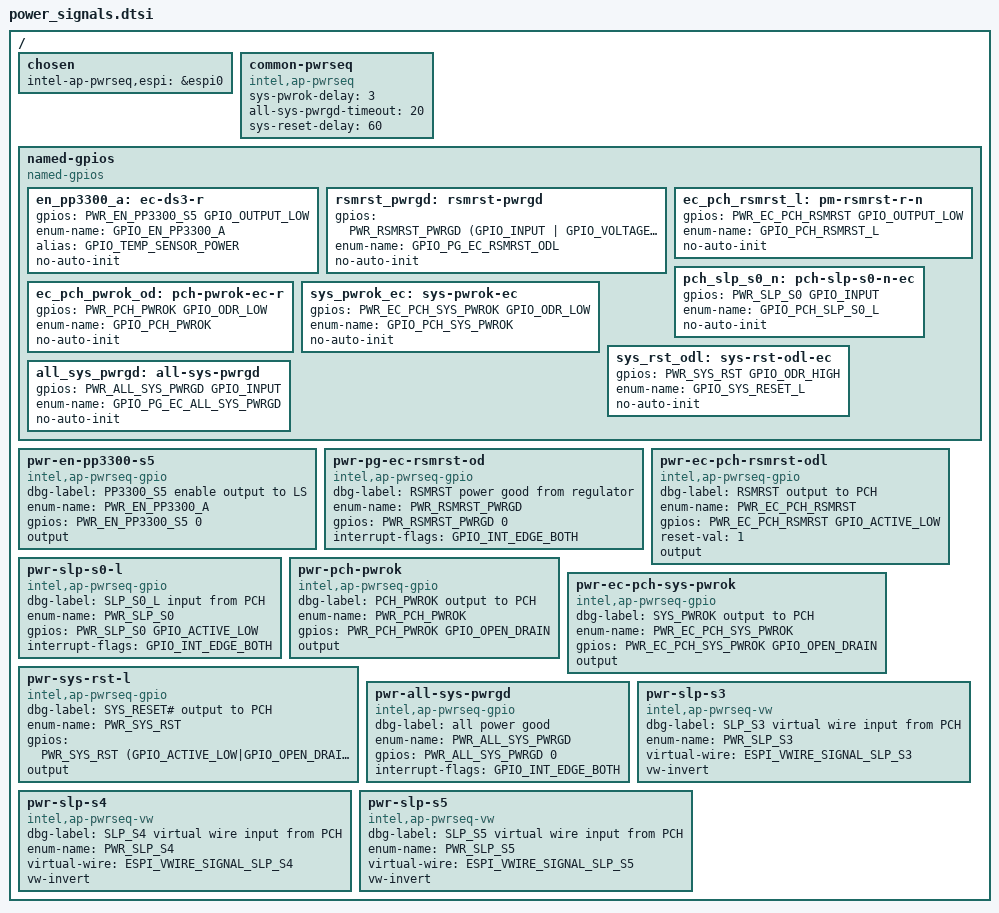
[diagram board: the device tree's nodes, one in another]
/* Copyright 2024 The ChromiumOS Authors
 * Use of this source code is governed by a BSD-style license that can be
 * found in the LICENSE file.
 */

/ {
        chosen {
		intel-ap-pwrseq,espi = &espi0;
	};

	common-pwrseq {
		compatible = "intel,ap-pwrseq";

		sys-pwrok-delay = <3>;
		all-sys-pwrgd-timeout = <20>;
		sys-reset-delay = <60>;
	};

	named-gpios {
		compatible = "named-gpios";

		en_pp3300_a: ec-ds3-r {
			gpios = <PWR_EN_PP3300_S5 GPIO_OUTPUT_LOW>;
			enum-name = "GPIO_EN_PP3300_A";
			alias = "GPIO_TEMP_SENSOR_POWER";
		};

		rsmrst_pwrgd: rsmrst-pwrgd {
			gpios = <PWR_RSMRST_PWRGD (GPIO_INPUT | GPIO_VOLTAGE_1P8)>;
			enum-name = "GPIO_PG_EC_RSMRST_ODL";
		};

		ec_pch_rsmrst_l: pm-rsmrst-r-n {
			gpios = <PWR_EC_PCH_RSMRST GPIO_OUTPUT_LOW>; /* 1.8V */
			enum-name = "GPIO_PCH_RSMRST_L";
		};

		pch_slp_s0_n: pch-slp-s0-n-ec {
			gpios = <PWR_SLP_S0 GPIO_INPUT>;
			enum-name = "GPIO_PCH_SLP_S0_L"; /* 1.8V */
		};

		ec_pch_pwrok_od: pch-pwrok-ec-r {
			gpios = <PWR_PCH_PWROK GPIO_ODR_LOW>;
			enum-name = "GPIO_PCH_PWROK";
		};

		sys_pwrok_ec: sys-pwrok-ec {
			gpios = <PWR_EC_PCH_SYS_PWROK GPIO_ODR_LOW>;
			enum-name = "GPIO_PCH_SYS_PWROK";
		};

		sys_rst_odl: sys-rst-odl-ec {
			gpios = <PWR_SYS_RST GPIO_ODR_HIGH>;
			enum-name = "GPIO_SYS_RESET_L";
		};

		all_sys_pwrgd: all-sys-pwrgd {
			gpios = <PWR_ALL_SYS_PWRGD GPIO_INPUT>;
			enum-name = "GPIO_PG_EC_ALL_SYS_PWRGD";
		};
	};

	pwr-en-pp3300-s5 {
		compatible = "intel,ap-pwrseq-gpio";
		dbg-label = "PP3300_S5 enable output to LS";
		enum-name = "PWR_EN_PP3300_A";
		gpios = <PWR_EN_PP3300_S5 0>;
		output;
	};

	pwr-pg-ec-rsmrst-od {
		compatible = "intel,ap-pwrseq-gpio";
		dbg-label = "RSMRST power good from regulator";
		enum-name = "PWR_RSMRST_PWRGD";
		gpios = <PWR_RSMRST_PWRGD 0>;
		interrupt-flags = <GPIO_INT_EDGE_BOTH>;
	};

	pwr-ec-pch-rsmrst-odl {
		compatible = "intel,ap-pwrseq-gpio";
		dbg-label = "RSMRST output to PCH";
		enum-name = "PWR_EC_PCH_RSMRST";
		gpios = <PWR_EC_PCH_RSMRST GPIO_ACTIVE_LOW>;
		reset-val = <1>;
		output;
	};

	pwr-slp-s0-l {
		compatible = "intel,ap-pwrseq-gpio";
		dbg-label = "SLP_S0_L input from PCH";
		enum-name = "PWR_SLP_S0";
		gpios = <PWR_SLP_S0 GPIO_ACTIVE_LOW>;
		interrupt-flags = <GPIO_INT_EDGE_BOTH>;
	};

	pwr-pch-pwrok {
		compatible = "intel,ap-pwrseq-gpio";
		dbg-label = "PCH_PWROK output to PCH";
		enum-name = "PWR_PCH_PWROK";
		gpios = <PWR_PCH_PWROK GPIO_OPEN_DRAIN>;
		output;
	};

	pwr-ec-pch-sys-pwrok {
		compatible = "intel,ap-pwrseq-gpio";
		dbg-label = "SYS_PWROK output to PCH";
		enum-name = "PWR_EC_PCH_SYS_PWROK";
		gpios = <PWR_EC_PCH_SYS_PWROK GPIO_OPEN_DRAIN>;
		output;
	};

	pwr-sys-rst-l {
		compatible = "intel,ap-pwrseq-gpio";
		dbg-label = "SYS_RESET# output to PCH";
		enum-name = "PWR_SYS_RST";
		gpios = <PWR_SYS_RST (GPIO_ACTIVE_LOW|GPIO_OPEN_DRAIN)>;
		output;
	};

	pwr-all-sys-pwrgd {
		compatible = "intel,ap-pwrseq-gpio";
		dbg-label = "all power good";
		enum-name = "PWR_ALL_SYS_PWRGD";
		gpios = <PWR_ALL_SYS_PWRGD 0>;
		interrupt-flags = <GPIO_INT_EDGE_BOTH>;
	};

        pwr-slp-s3 {
		compatible = "intel,ap-pwrseq-vw";
		dbg-label = "SLP_S3 virtual wire input from PCH";
		enum-name = "PWR_SLP_S3";
		virtual-wire = "ESPI_VWIRE_SIGNAL_SLP_S3";
		vw-invert;
	};

	pwr-slp-s4 {
		compatible = "intel,ap-pwrseq-vw";
		dbg-label = "SLP_S4 virtual wire input from PCH";
		enum-name = "PWR_SLP_S4";
		virtual-wire = "ESPI_VWIRE_SIGNAL_SLP_S4";
		vw-invert;
	};

	pwr-slp-s5 {
		compatible = "intel,ap-pwrseq-vw";
		dbg-label = "SLP_S5 virtual wire input from PCH";
		enum-name = "PWR_SLP_S5";
		virtual-wire = "ESPI_VWIRE_SIGNAL_SLP_S5";
		vw-invert;
	};
};

/*
 * Because the power signals directly reference the GPIOs,
 * the correspinding named-gpios need to have no-auto-init set.
 */
&en_pp3300_a {
	no-auto-init;
};
&rsmrst_pwrgd {
	no-auto-init;
};
&ec_pch_rsmrst_l {
	no-auto-init;
};
&pch_slp_s0_n {
	no-auto-init;
};
&ec_pch_pwrok_od {
	no-auto-init;
};
&sys_pwrok_ec {
	no-auto-init;
};
&sys_rst_odl {
	no-auto-init;
};
&all_sys_pwrgd {
	no-auto-init;
};
